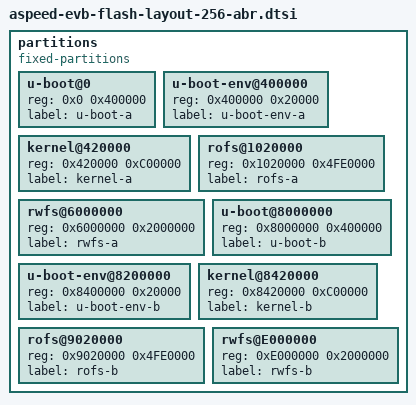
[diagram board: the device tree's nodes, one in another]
// SPDX-License-Identifier: GPL-2.0+

partitions {
	compatible = "fixed-partitions";
	#address-cells = <1>;
	#size-cells = <1>;

	u-boot@0 {
		reg = <0x0 0x400000>; // 4MB
		label = "u-boot-a";
	};

	u-boot-env@400000 {
		reg = <0x400000 0x20000>; // 128KB
		label = "u-boot-env-a";
	};

	kernel@420000 {
		reg = <0x420000 0xC00000>; // 12MB
		label = "kernel-a";
	};

	rofs@1020000 {
		reg = <0x1020000 0x4FE0000>; // 79.875MB
		label = "rofs-a";
	};

	rwfs@6000000 {
		reg = <0x6000000 0x2000000>; // 32MB
		label = "rwfs-a";
	};

	u-boot@8000000 {
		reg = <0x8000000 0x400000>; // 4MB
		label = "u-boot-b";
	};

	u-boot-env@8200000 {
		reg = <0x8400000 0x20000>; // 128KB
		label = "u-boot-env-b";
	};

	kernel@8420000 {
		reg = <0x8420000 0xC00000>; // 12MB
		label = "kernel-b";
	};

	rofs@9020000 {
		reg = <0x9020000 0x4FE0000>; // 79.875MB
		label = "rofs-b";
	};

	rwfs@E000000 {
		reg = <0xE000000 0x2000000>; // 32MB
		label = "rwfs-b";
	};
};
